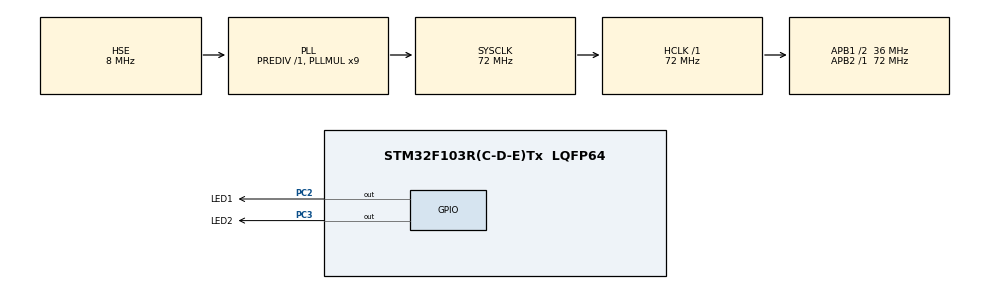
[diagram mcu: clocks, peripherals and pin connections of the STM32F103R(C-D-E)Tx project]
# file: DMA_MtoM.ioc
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Dma.MEMTOMEM.0.Direction=DMA_MEMORY_TO_MEMORY
Dma.MEMTOMEM.0.Instance=DMA1_Channel1
Dma.MEMTOMEM.0.MemDataAlignment=DMA_MDATAALIGN_WORD
Dma.MEMTOMEM.0.MemInc=DMA_MINC_ENABLE
Dma.MEMTOMEM.0.Mode=DMA_NORMAL
Dma.MEMTOMEM.0.PeriphDataAlignment=DMA_PDATAALIGN_WORD
Dma.MEMTOMEM.0.PeriphInc=DMA_PINC_ENABLE
Dma.MEMTOMEM.0.Priority=DMA_PRIORITY_MEDIUM
Dma.Request0=MEMTOMEM
Mcu.Family=STM32F1
Mcu.Name=STM32F103R(C-D-E)Tx
Mcu.Package=LQFP64
NVIC.PriorityGroup=NVIC_PRIORITYGROUP_4
PC2.GPIO_Label=LED1
PC2.GPIO_Speed=GPIO_SPEED_FREQ_LOW
PC2.Signal=GPIO_Output
PC3.GPIO_Label=LED2
PC3.Signal=GPIO_Output
PD0-OSC_IN.Mode=HSE-External-Oscillator
PD0-OSC_IN.Signal=RCC_OSC_IN
PD1-OSC_OUT.Mode=HSE-External-Oscillator
PD1-OSC_OUT.Signal=RCC_OSC_OUT
ProjectManager.HeapSize=0x200
ProjectManager.StackSize=0x400
ProjectManager.TargetToolchain=Makefile
RCC.AHBFreq_Value=72000000
RCC.APB1CLKDivider=RCC_HCLK_DIV2
RCC.APB1Freq_Value=36000000
RCC.APB1TimFreq_Value=72000000
RCC.APB2Freq_Value=72000000
RCC.APB2TimFreq_Value=72000000
RCC.HCLKFreq_Value=72000000
RCC.PLLMUL=RCC_PLL_MUL9
RCC.PLLSourceVirtual=RCC_PLLSOURCE_HSE
RCC.SYSCLKFreq_VALUE=72000000
RCC.SYSCLKSource=RCC_SYSCLKSOURCE_PLLCLK
RCC.USBFreq_Value=72000000
VP_SYS_VS_ND.Mode=No_Debug
board=custom

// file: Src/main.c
/* USER CODE BEGIN Header */
/**
  ******************************************************************************
  * @file           : main.c
  * @brief          : Main program body
  ******************************************************************************
  * @attention
  *
  * <h2><center>&copy; Copyright (c) 2020 STMicroelectronics.
  * All rights reserved.</center></h2>
  *
  * This software component is licensed by ST under BSD 3-Clause license,
  * the "License"; You may not use this file except in compliance with the
  * License. You may obtain a copy of the License at:
  *                        opensource.org/licenses/BSD-3-Clause
  *
  ******************************************************************************
  */
/* USER CODE END Header */

#include "main.h"
#include "dma.h"
#include "gpio.h"

void SystemClock_Config(void);

/* USER CODE BEGIN 0 */
#define DMA_STREAM DMA1_Channel6
#define DMA_STREAM_CLOCK() __HAL_RCC_DMA1_CLK_ENABLE();
#define BUFFER_SIZE 32

/* 定义aSRC_Const_Buffer数组作为DMA传输数据源
  const关键字将aSRC_Const_Buffer数组变量定义为常量类型 */
const uint32_t aSRC_Const_Buffer[BUFFER_SIZE] = {
    0x01020304, 0x05060708, 0x090A0B0C, 0x0D0E0F10,
    0x11121314, 0x15161718, 0x191A1B1C, 0x1D1E1F20,
    0x21222324, 0x25262728, 0x292A2B2C, 0x2D2E2F30,
    0x31323334, 0x35363738, 0x393A3B3C, 0x3D3E3F40,
    0x41424344, 0x45464748, 0x494A4B4C, 0x4D4E4F50,
    0x51525354, 0x55565758, 0x595A5B5C, 0x5D5E5F60,
    0x61626364, 0x65666768, 0x696A6B6C, 0x6D6E6F70,
    0x71727374, 0x75767778, 0x797A7B7C, 0x7D7E7F80};
/* 定义DMA传输目标存储器 */
uint32_t aDST_Buffer[BUFFER_SIZE];

static void Delay(__IO uint32_t nCount);
uint8_t Buffercmp(const uint32_t *pBuffer, uint32_t *pBuffer1, uint16_t BufferLength);
/* USER CODE END 0 */

int main(void)
{
    /* USER CODE BEGIN 1 */
    uint8_t TransferStatus;
    HAL_StatusTypeDef DMA_status = HAL_ERROR;
    /* USER CODE END 1 */

    /* MCU Configuration--------------------------------------------------------*/

    /* Reset of all peripherals, Initializes the Flash interface and the Systick. */
    HAL_Init();

    /* Configure the system clock */
    SystemClock_Config();

    /* Initialize all configured peripherals */
    MX_GPIO_Init();
    MX_DMA_Init();
    /* USER CODE BEGIN 2 */
    DMA_status = HAL_DMA_Start(&hdma_memtomem_dma1_channel1, (uint32_t)aSRC_Const_Buffer, (uint32_t)aDST_Buffer, BUFFER_SIZE);

    /* 判断DMA状态 */
    if (DMA_status != HAL_OK)
    {
        /* DMA出错就让程序运行下面循环：RGB彩色灯闪烁 */
        while (1)
        {
            LED1_ON;
            Delay(0xFFFFFF);
            LED1_TOGGLE;
            Delay(0xFFFFFF);
        }
    }

    while (__HAL_DMA_GET_FLAG(&hdma_memtomem_dma1_channel1, DMA_FLAG_TC1) == RESET)
    {
    }
    //LED1_ON;
    TransferStatus = Buffercmp(aSRC_Const_Buffer, aDST_Buffer, 32);

    if (TransferStatus == 0)
    {
        LED1_ON;
    }
    else
    {
        LED2_ON;
    }

    /* USER CODE END 2 */

    /* Infinite loop */
    while (1)
    {
        // LED1_TOGGLE;
        // HAL_Delay(1000);
    }
}

void SystemClock_Config(void)
{
    RCC_OscInitTypeDef RCC_OscInitStruct = {0};
    RCC_ClkInitTypeDef RCC_ClkInitStruct = {0};

    /** Initializes the CPU, AHB and APB busses clocks
  */
    RCC_OscInitStruct.OscillatorType = RCC_OSCILLATORTYPE_HSE;
    RCC_OscInitStruct.HSEState = RCC_HSE_ON;
    RCC_OscInitStruct.HSEPredivValue = RCC_HSE_PREDIV_DIV1;
    RCC_OscInitStruct.HSIState = RCC_HSI_ON;
    RCC_OscInitStruct.PLL.PLLState = RCC_PLL_ON;
    RCC_OscInitStruct.PLL.PLLSource = RCC_PLLSOURCE_HSE;
    RCC_OscInitStruct.PLL.PLLMUL = RCC_PLL_MUL9;
    if (HAL_RCC_OscConfig(&RCC_OscInitStruct) != HAL_OK)
    {
        Error_Handler();
    }
    /** Initializes the CPU, AHB and APB busses clocks
  */
    RCC_ClkInitStruct.ClockType = RCC_CLOCKTYPE_HCLK | RCC_CLOCKTYPE_SYSCLK | RCC_CLOCKTYPE_PCLK1 | RCC_CLOCKTYPE_PCLK2;
    RCC_ClkInitStruct.SYSCLKSource = RCC_SYSCLKSOURCE_PLLCLK;
    RCC_ClkInitStruct.AHBCLKDivider = RCC_SYSCLK_DIV1;
    RCC_ClkInitStruct.APB1CLKDivider = RCC_HCLK_DIV2;
    RCC_ClkInitStruct.APB2CLKDivider = RCC_HCLK_DIV1;

    if (HAL_RCC_ClockConfig(&RCC_ClkInitStruct, FLASH_LATENCY_2) != HAL_OK)
    {
        Error_Handler();
    }
}

/* USER CODE BEGIN 4 */
static void Delay(__IO uint32_t nCount)
{
    for (; nCount != 0; nCount--)
        ;
}

uint8_t Buffercmp(const uint32_t *pBuffer,
                  uint32_t *pBuffer1, uint16_t BufferLength)
{
    /* 数据长度递减 */
    while (BufferLength--)
    {
        /* 判断两个数据源是否对应相等 */
        if (*pBuffer != *pBuffer1)
        {
            /* 对应数据源不相等马上退出函数，并返回0 */
            return 0;
        }
        /* 递增两个数据源的地址指针 */
        pBuffer++;
        pBuffer1++;
    }
    /* 完成判断并且对应数据相对 */
    return 1;
}
/* USER CODE END 4 */

void Error_Handler(void)
{
}

/************************ (C) COPYRIGHT STMicroelectronics *****END OF FILE****/
